AUTOSAR XML (schema 00048)
package /AdaptiveApplicationSwComponentTypes
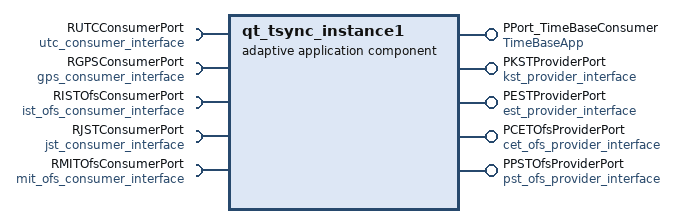
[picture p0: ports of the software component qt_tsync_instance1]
  adaptive application sw component type qt_tsync_instance1: category=APPLICATION_LEVEL
    provide port PPort_TimeBaseConsumer: provided-interface=TimeBaseApp
    require port RUTCConsumerPort: required-interface=utc_consumer_interface
    require port RGPSConsumerPort: required-interface=gps_consumer_interface
    require port RISTOfsConsumerPort: required-interface=ist_ofs_consumer_interface
    4 x provide port:
      PKSTProviderPort: provided-interface=kst_provider_interface
      PESTProviderPort: provided-interface=est_provider_interface
      PCETOfsProviderPort: provided-interface=cet_ofs_provider_interface
      PPSTOfsProviderPort: provided-interface=pst_ofs_provider_interface
    require port RJSTConsumerPort: required-interface=jst_consumer_interface
    require port RMITOfsConsumerPort: required-interface=mit_ofs_consumer_interface
  adaptive application sw component type tsync_core
package /Executables
  executable qt_tsync_instance1
    root sw component prototype tsync_instance_1_rootSwComponentPrototype: application-type=qt_tsync_instance1
  executable tsync_core
    root sw component prototype rootSwComponentPrototype: application-type=tsync_core
package /ProcessDesign
  process design qt_tsync_instance1: executable=qt_tsync_instance1
  process design tsync_coreProcessDesign: executable=tsync_core
package /DataTypes
  7 x std cpp implementation data type:
    ReturnTimeWithStatus: category=STRUCTURE
      namespaces:
        symbol props ara
        symbol props tsync
        symbol props types
      4 x cpp implementation data type element:
        syncStatus: type-reference=uint32_t
        leapJump: type-reference=uint32_t
        userData: type-reference=ByteArray
        updateCount: type-reference=uint8_t
    ReturnTimeSlaveMeasurementType: category=STRUCTURE
      namespaces:
        symbol props ara
        symbol props tsync
        symbol props types
      6 x cpp implementation data type element:
        preciseOriginTimeStampOutput: type-reference=TimeStamp
        referenceGlobalTimestampOutput: type-reference=TimeStamp
        syncIngressTimestampOutput: type-reference=uint64_t
        correctionFieldOutput: type-reference=int64_t
        referenceLocalTimestamp: type-reference=uint64_t
        pDelayOutput: type-reference=uint32_t
    ReturnTimeMasterMeasurementType: category=STRUCTURE
      namespaces:
        symbol props ara
        symbol props tsync
        symbol props types
      cpp implementation data type element preciseOriginTimestampOutput: type-reference=TimeStamp
      cpp implementation data type element syncEgressTimestampOutput: type-reference=uint64_t
      cpp implementation data type element sequenceIdOutput: type-reference=uint16_t
    ReturnPdelayInitiatorMeasurementType: category=STRUCTURE
      namespaces:
        symbol props ara
        symbol props tsync
        symbol props types
      8 x cpp implementation data type element:
        requestOriginTimestampOutput: type-reference=uint64_t
        responseReceiptTimestampOutput: type-reference=uint64_t
        requestRecieptTimestampOutput: type-reference=TimeStamp
        responseOriginTimestampOutput: type-reference=TimeStamp
        referenceLocalTimeStampOutput: type-reference=uint64_t
        referenceGlobalTimeStampOutput: type-reference=TimeStamp
        pDelayOutput: type-reference=uint32_t
        sequenceIdOutput: type-reference=uint16_t
    ReturnPdelayResponderMeasurementType: category=STRUCTURE
      namespaces:
        symbol props ara
        symbol props tsync
        symbol props types
      5 x cpp implementation data type element:
        requestRecieptTimestampOutput: type-reference=uint64_t
        responseOriginTimestampOutput: type-reference=uint64_t
        referenceLocalTimestampOutput: type-reference=uint64_t
        referenceGlobalTimestampOutput: type-reference=TimeStamp
        sequenceIdOutput: type-reference=uint16_t
    ReturnTimePrecisionMeasurementType: category=STRUCTURE
      namespaces:
        symbol props ara
        symbol props tsync
        symbol props types
      8 x cpp implementation data type element:
        glbSecondsOutput: type-reference=uint32_t
        glbNanoSecondsOutput: type-reference=uint32_t
        timebaseStatusOutput: type-reference=uint8_t
        virtualLocalTimeLowOutput: type-reference=uint32_t
        rateDeviationOutput: type-reference=int16_t
        locSecondsOutput: type-reference=uint32_t
        locNanoSecondsOutput: type-reference=uint32_t
        pathDelayOutput: type-reference=uint32_t
    TimeStamp: type-reference=int64_t
      namespaces:
        symbol props ara
        symbol props tsync
        symbol props types
